# STM32G544 register map
File version: 2.0.0
CPU: CM33 r0p4, little endian, MPU, FPU, 4 interrupt priority bits
Registers are 32-bit, read-write, reset 0x0 unless marked. A register's access mark holds for its fields unless they carry their own. Offsets are from the block's base; [hi:lo] are bit positions.

## CRC — CRC address block description
Base 0x40023000
Same registers: CRC_S 0x50023000
0x00 CRC_DR reset 0xFFFFFFFF — CRC data register
  [31:0] DR — Data register bits
0x04 CRC_IDR — CRC independent data register
  [31:0] IDR — General-purpose 32-bit data register bits
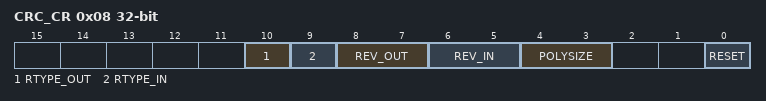
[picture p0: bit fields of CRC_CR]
0x08 CRC_CR — CRC control register
  [10] RTYPE_OUT — Reverse type output
    0=Bit level output; 1=Byte or half-word level output
  [9] RTYPE_IN — Reverse type input
    0=Bit level input; 1=Byte or half-word level input
  [8:7] REV_OUT — Reverse output data
    0=Bit order not affected (RTYPE_OUT=0 or 1); 1=Bit-reversed output format (RTYPE_OUT=0) or half-word reversal done by word (RTYPE_OUT=1); 2=Bit order not affected (RTYPE_OUT=0) or byte reversal done by word (RTYPE_OUT=1); 3=Bit order not affected (RTYPE_OUT=0 or 1)
  [6:5] REV_IN — Reverse input data
    0=Bit order not affected (RTYPE_IN=0 or 1); 1=Bit reversal done by byte (RTYPE_IN=0) or half-word reversal done by word (RTYPE_IN=1); 2=Bit reversal done by half-word (RTYPE_IN=0) or byte reversal done by word (RTYPE_IN=1); 3=Bit reversal done by word (RTYPE_IN=0) or bit order is not affected (RTYPE_IN=1)
  [4:3] POLYSIZE — Polynomial size
    0=32 bit polynomial; 1=16 bit polynomial; 2=8 bit polynomial; 3=7 bit polynomial
  [0] RESET — RESET bit
0x10 CRC_INIT reset 0xFFFFFFFF — CRC initial value
  [31:0] CRC_INIT — Programmable initial CRC value
0x14 CRC_POL reset 0x4C11DB7 — CRC polynomial
  [31:0] POL — Programmable polynomial

## FMAC1 — FMAC register block
Base 0x40023C00
Same registers: FMAC1_S 0x50023C00
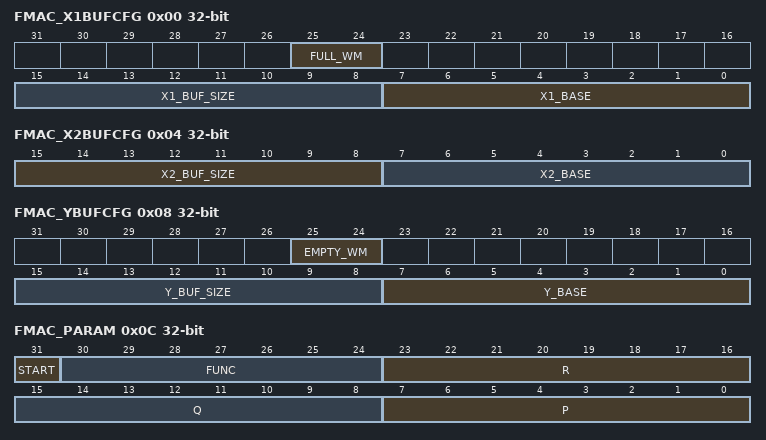
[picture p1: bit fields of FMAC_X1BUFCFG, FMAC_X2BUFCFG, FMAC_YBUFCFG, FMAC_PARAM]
0x00 FMAC_X1BUFCFG — FMAC X1 buffer configuration register
  [25:24] FULL_WM — Watermark for buffer full flag
    0=Threshold = 1; 1=Threshold = 2
  [15:8] X1_BUF_SIZE — Allocated size of X1 buffer in 16-bit words
  [7:0] X1_BASE — Base address of X1 buffer
0x04 FMAC_X2BUFCFG — FMAC X2 buffer configuration register
  [15:8] X2_BUF_SIZE — Size of X2 buffer in 16-bit words
  [7:0] X2_BASE — Base address of X2 buffer
0x08 FMAC_YBUFCFG — FMAC Y buffer configuration register
  [25:24] EMPTY_WM — Watermark for buffer empty flag
    0=Threshold = 1; 1=Threshold = 2
  [15:8] Y_BUF_SIZE — Size of Y buffer in 16-bit words
  [7:0] Y_BASE — Base address of Y buffer
0x0C FMAC_PARAM — FMAC parameter register
  [31] START — Enable execution
    0=Stop execution; 1=Start execution
  [30:24] FUNC — Function
    1=Load X1 buffer
  [23:16] R — Input parameter R.
  [15:8] Q — Input parameter Q.
  [7:0] P — Input parameter P.
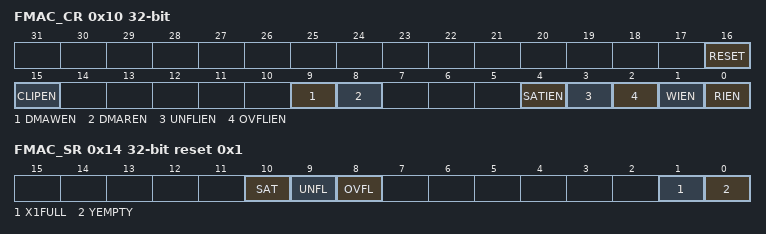
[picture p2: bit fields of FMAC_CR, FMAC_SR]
0x10 FMAC_CR — FMAC control register
  [16] RESET — Reset FMAC unit
    0=Reset inactive; 1=Reset active
  [15] CLIPEN — Enable clipping
    0=Clipping disabled; 1=Clipping enabled
  [9] DMAWEN — Enable DMA write channel requests
    0=Disable; 1=Enable
  [8] DMAREN — Enable DMA read channel requests
    0=Disable; 1=Enable
  [4] SATIEN — Enable saturation error interrupts
    0=Disabled; 1=Enabled
  [3] UNFLIEN — Enable underflow error interrupts
    0=Disabled; 1=Enabled
  [2] OVFLIEN — Enable overflow error interrupts
    0=Disabled; 1=Enabled
  [1] WIEN — Enable write interrupt
    0=Disabled; 1=Enabled
  [0] RIEN — Enable read interrupt
    0=Disabled; 1=Enabled
0x14 FMAC_SR ro reset 0x1 — FMAC status register
  [10] SAT — Saturation error flag
    0=No saturation detected; 1=Saturation detected
  [9] UNFL — Underflow error flag
    0=No underflow detected; 1=Underflow detected
  [8] OVFL — Overflow error flag
    0=No overflow detected; 1=Overflow detected
  [1] X1FULL — X1 buffer full flag
    0=X1 buffer not full; 1=X1 buffer full
  [0] YEMPTY — Y buffer empty flag
    0=Y buffer not empty; 1=Y buffer empty
0x18 FMAC_WDATA wo — FMAC write data register
  [15:0] WDATA — Write data
0x1C FMAC_RDATA ro — FMAC read data register
  [15:0] RDATA — Read data
